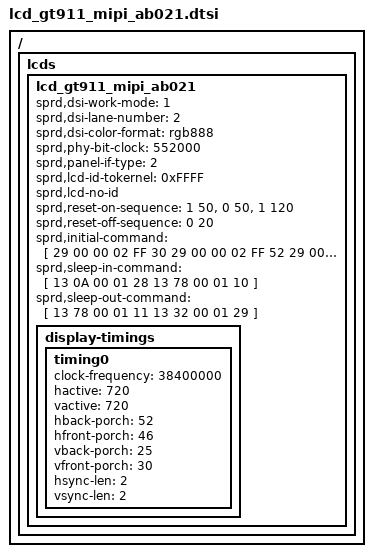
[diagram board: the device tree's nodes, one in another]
/*
 * RG Rotate 720x720 MIPI LCD config dtsi file for spreadtrum
 *
 * SPDX-License-Identifier: (GPL-2.0+ OR MIT)
 */

/ { lcds {
	lcd_gt911_mipi_ab021: lcd_gt911_mipi_ab021 {
		sprd,dsi-work-mode = <1>;
		sprd,dsi-lane-number = <2>;
		sprd,dsi-color-format = "rgb888";
		sprd,phy-bit-clock = <552000>;
		sprd,panel-if-type = <2>;
		sprd,lcd-id-tokernel = <0xFFFF>;
		sprd,lcd-no-id;
		sprd,reset-on-sequence = <1 50>, <0 50>, <1 120>;
		sprd,reset-off-sequence = <0 20>;

		sprd,initial-command = [
			29 00 00 02 FF 30
			29 00 00 02 FF 52
			29 00 00 02 FF 01
			29 00 00 02 E3 00

			29 00 00 02 25 0A
			29 00 00 02 28 5F
			29 00 00 02 29 C2
			29 00 00 02 2A CF
			29 00 00 02 30 58
			29 00 00 02 37 9C
			29 00 00 02 38 A7
			29 00 00 02 39 1F
			29 00 00 02 44 00
			29 00 00 02 49 3C
			29 00 00 02 59 FE
			29 00 00 02 5C 00
			29 00 00 02 80 20
			29 00 00 02 91 77
			29 00 00 02 92 77
			29 00 00 02 A0 55
			29 00 00 02 A1 50
			29 00 00 02 A3 58
			29 00 00 02 A4 9C
			29 00 00 02 A7 02
			29 00 00 02 A8 01
			29 00 00 02 A9 01
			29 00 00 02 AA FC
			29 00 00 02 AB 28
			29 00 00 02 AC 06
			29 00 00 02 AD 06
			29 00 00 02 AE 06
			29 00 00 02 AF 03
			29 00 00 02 B0 08
			29 00 00 02 B1 26
			29 00 00 02 B2 28
			29 00 00 02 B3 28
			29 00 00 02 B4 03
			29 00 00 02 B5 08
			29 00 00 02 B6 26
			29 00 00 02 B7 08
			29 00 00 02 B8 26
			29 00 00 02 C0 00
			29 00 00 02 C1 00
			29 00 00 02 C2 00
			29 00 00 02 C3 0F
			29 00 00 02 FF 30
			29 00 00 02 FF 52
			29 00 00 02 FF 02
			29 00 00 02 B0 00
			29 00 00 02 B1 0F
			29 00 00 02 B2 12
			29 00 00 02 B3 32
			29 00 00 02 B4 24
			29 00 00 02 B5 3F
			29 00 00 02 B6 25
			29 00 00 02 B7 3F
			29 00 00 02 B8 0E
			29 00 00 02 B9 06
			29 00 00 02 BA 11
			29 00 00 02 BB 10
			29 00 00 02 BC 10
			29 00 00 02 BD 13
			29 00 00 02 BE 1B
			29 00 00 02 BF 10
			29 00 00 02 C0 17
			29 00 00 02 C1 08
			29 00 00 02 D0 00
			29 00 00 02 D1 0D
			29 00 00 02 D2 12
			29 00 00 02 D3 2A
			29 00 00 02 D4 2E
			29 00 00 02 D5 3F
			29 00 00 02 D6 29
			29 00 00 02 D7 43
			29 00 00 02 D8 10
			29 00 00 02 D9 08
			29 00 00 02 DA 13
			29 00 00 02 DB 10
			29 00 00 02 DC 12
			29 00 00 02 DD 13
			29 00 00 02 DE 1F
			29 00 00 02 DF 1A
			29 00 00 02 E0 1F
			29 00 00 02 E1 0A
			29 00 00 02 FF 30
			29 00 00 02 FF 52
			29 00 00 02 FF 03
			29 00 00 02 04 51
			29 00 00 02 05 C0
			29 00 00 02 06 C0
			29 00 00 02 08 86
			29 00 00 02 09 87
			29 00 00 02 0A 84
			29 00 00 02 0B 85
			29 00 00 02 28 33
			29 00 00 02 29 33
			29 00 00 02 2A EB
			29 00 00 02 2B EA
			29 00 00 02 2C ED
			29 00 00 02 2D EC
			29 00 00 02 34 81
			29 00 00 02 35 53
			29 00 00 02 37 23
			29 00 00 02 40 84
			29 00 00 02 41 85
			29 00 00 02 42 82
			29 00 00 02 43 83
			29 00 00 02 44 33
			29 00 00 02 45 EA
			29 00 00 02 46 E9
			29 00 00 02 47 33
			29 00 00 02 48 EC
			29 00 00 02 49 EB
			29 00 00 02 50 80
			29 00 00 02 51 81
			29 00 00 02 52 02
			29 00 00 02 53 01
			29 00 00 02 54 33
			29 00 00 02 55 EE
			29 00 00 02 56 ED
			29 00 00 02 57 33
			29 00 00 02 58 F0
			29 00 00 02 59 EF
			29 00 00 02 80 00
			29 00 00 02 81 01
			29 00 00 02 82 06
			29 00 00 02 83 07
			29 00 00 02 84 04
			29 00 00 02 85 05
			29 00 00 02 92 03
			29 00 00 02 93 02
			29 00 00 02 96 00
			29 00 00 02 97 01
			29 00 00 02 98 06
			29 00 00 02 99 07
			29 00 00 02 9A 04
			29 00 00 02 9B 05
			29 00 00 02 A8 03
			29 00 00 02 A9 02
			29 00 00 02 FF 30
			29 00 00 02 FF 52
			29 00 00 02 FF 00
			29 00 00 02 36 01
			29 00 00 02 53 2C
			05 C8 00 02 11 00
			05 64 00 02 29 00
		];

		sprd,sleep-in-command = [
			13 0A 00 01 28
			13 78 00 01 10
		];

		sprd,sleep-out-command = [
			13 78 00 01 11
			13 32 00 01 29
		];

		display-timings {
			timing0: timing0 {
				clock-frequency = <38400000>;
				hactive = <720>;
				vactive = <720>;
				hback-porch = <52>;
				hfront-porch = <46>;
				vback-porch = <25>;
				vfront-porch = <30>;
				hsync-len = <2>;
				vsync-len = <2>;
			};
		};
	};
};};
